# NUC1261AE_v1 register map
File version: 1.0
Registers are 32-bit, read-write, reset 0x0 unless marked. A register's access mark holds for its fields unless they carry their own. Offsets are from the block's base; [hi:lo] are bit positions.

## HDIV — HDIV Register Map
Base 0x50014000
0x00 HDIV_DIVIDEND — Dividend Source Register
  [31:0] DIVIDEND — Dividend Source. This register is given the dividend of divider before calculation starting.
0x04 HDIV_DIVISOR reset 0xFFFF — Divisor Source Resister
  [15:0] DIVISOR — Divisor Source. This register is given the divisor of divider before calculation starts. Note: When this register is written, hardware divider will start calculate.
0x08 HDIV_DIVQUO — Quotient Result Resister
  [31:0] QUOTIENT — Quotient Result. This register holds the quotient result of divider after calculation complete.
0x0C HDIV_DIVREM — Remainder Result Register
  [31:0] REMAINDER — Remainder Result. The remainder of hardware divider is 16-bit sign integer (REMAINDER[15:0]), which holds the remainder result of divider after calculation complete. The remainder of hardware divider with sign extension (REMAINDER[31:16]) to 32-bit integer. This register holds the remainder result of divider after calculation complete.
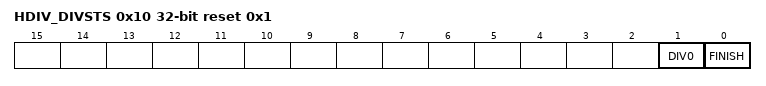
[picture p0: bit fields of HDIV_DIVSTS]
0x10 HDIV_DIVSTS ro reset 0x1 — Divider Status Register
  [1] DIV0 — Divisor Zero Warning. Note: The DIV0 flag is used to indicate divide-by-zero situation and updated whenever DIVISOR is written. This register is read only.
    0=The divisor is not 0; 1=The divisor is 0
  [0] FINISH — Division Finish Flag. The flag will become low when the divider is in calculation. The flag will go back to high once the calculation finished.
    0=Under Calculation; 1=Calculation finished

## WWDT — WWDT Register Map
Base 0x40004100
0x00 WWDT_RLDCNT wo — WWDT Reload Counter Register
  [31:0] RLDCNT — WWDT Reload Counter Register. Writing only 0x00005AA5 to this register will reload the WWDT counter value to 0x3F. Note1: User can only execute the reload WWDT counter value command when current CNTDAT (WWDT_CNT[5:0]) is between 1 and CMPDAT (WWDT_CTL[21:16]). If user writes 0x00005AA5 in WWDT_RLDCNT register when current CNTDAT is larger than CMPDAT, WWDT reset system event will be generated immediately. Note2: Executing WWDT counter reload always needs (WWDT_CLK *3) period to reload CNTDAT to 0x3F and internal prescale counter will be reset also.
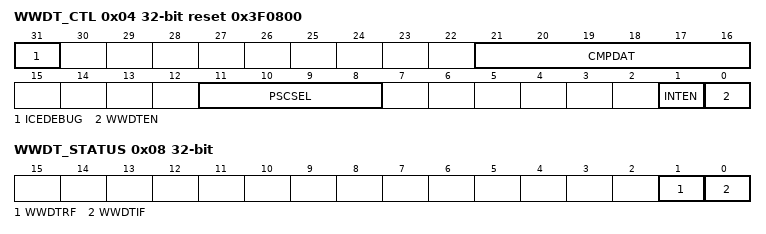
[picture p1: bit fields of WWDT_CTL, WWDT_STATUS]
0x04 WWDT_CTL reset 0x3F0800 — WWDT Control Register
  [31] ICEDEBUG — ICE Debug Mode Acknowledge Disable Bit. The WWDT down counter will keep counting no matter CPU is held by ICE or not.
    0=ICE debug mode acknowledgement effects WWDT counter counting; 1=ICE debug mode acknowledgement Disabled
  [21:16] CMPDAT — WWDT Window Compare Value. Set this field to adjust the valid reload window interval when WWDTIF (WWDT_STATUS[0]) is generated. Note: User can only write WWDT_RLDCNT register to reload WWDT counter value when current CNTDAT (WWDT_CNT[5:0]) is between 1 and CMPDAT. If user writes 0x00005AA5 in WWDT_RLDCNT register when current CNTDAT is larger than CMPDAT, WWDT reset system event will be generated immediately.
  [11:8] PSCSEL — WWDT Counter Prescale Period Selection
    0=Pre-scale is 1; Max time-out period is 1 * 64 * WWDT_CLK; 1=Pre-scale is 2; Max time-out period is 2 * 64 * WWDT_CLK; 2=Pre-scale is 4; Max time-out period is 4 * 64 * WWDT_CLK; 3=Pre-scale is 8; Max time-out period is 8 * 64 * WWDT_CLK; 4=Pre-scale is 16; Max time-out period is 16 * 64 * WWDT_CLK; 5=Pre-scale is 32; Max time-out period is 32 * 64 * WWDT_CLK; 6=Pre-scale is 64; Max time-out period is 64 * 64 * WWDT_CLK; 7=Pre-scale is 128; Max time-out period is 128 * 64 * WWDT_CLK; 8=Pre-scale is 192; Max time-out period is 192 * 64 * WWDT_CLK; 9=Pre-scale is 256; Max time-out period is 256 * 64 * WWDT_CLK; 10=Pre-scale is 384; Max time-out period is 384 * 64 * WWDT_CLK; 11=Pre-scale is 512; Max time-out period is 512 * 64 * WWDT_CLK; 12=Pre-scale is 768; Max time-out period is 768 * 64 * WWDT_CLK; 13=Pre-scale is 1024; Max time-out period is 1024 * 64 * WWDT_CLK; 14=Pre-scale is 1536; Max time-out period is 1536 * 64 * WWDT_CLK; 15=Pre-scale is 2048; Max time-out period is 2048 * 64 * WWDT_CLK
  [1] INTEN — WWDT Interrupt Enable Bit. If this bit is enabled, when WWDTIF (WWDT_STATUS[0]) is set to 1, the WWDT counter compare match interrupt signal is generated and inform to CPU.
    0=WWDT counter compare match interrupt disabled; 1=WWDT counter compare match interrupt enabled
  [0] WWDTEN — WWDT Enable Bit. Set this bit to start WWDT counter counting.
    0=WWDT counter is stopped; 1=WWDT counter is starting counting
0x08 WWDT_STATUS
  [1] WWDTRF — WWDT Timer-out Reset System Flag. If this bit is set to 1, it indicates that system has been reset by WWDT counter time-out reset system event. Note: This bit is cleared by writing 1 to it.
    0=WWDT time-out reset system event did not occur; 1=WWDT time-out reset system event occurred
  [0] WWDTIF — WWDT Compare Match Interrupt Flag. This bit indicates that current CNTDAT (WWDT_CNT[5:0]) matches the CMPDAT (WWDT_CTL[21:16]). Note: This bit is cleared by writing 1 to it.
    0=No effect; 1=WWDT CNTDAT matches the CMPDAT
0x0C WWDT_CNT ro reset 0x3F — WWDT Counter Value Register
  [5:0] CNTDAT — WWDT Counter Value. CNTDAT will be updated continuously.
